AUTOSAR XML (schema 4-2-2)
package /Components
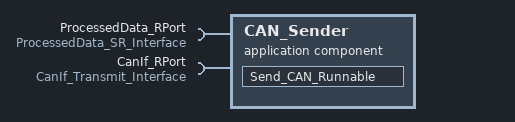
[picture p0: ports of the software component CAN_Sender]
  application sw component type CAN_Sender
    require port ProcessedData_RPort: required-interface=ProcessedData_SR_Interface
    require port CanIf_RPort: required-interface=CanIf_Transmit_Interface
    behavior CAN_Sender_Behavior
      data received event ProcessedData_Received_Event: start-on-event=Process_Data_Runnable
      runnable Send_CAN_Runnable: minimum-start-interval=100, symbol=Send_CAN_Runnable_Symbol
        data-receive-point-by-arguments:
          access ProcessedData_Access: accessed-variable=ProcessedData_PPort.ProcessedData
        sync call CanIf_Transmit_Call: operation=CanIf_RPort.Transmit, timeout=50
